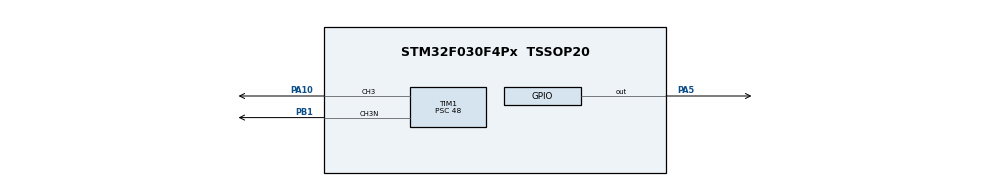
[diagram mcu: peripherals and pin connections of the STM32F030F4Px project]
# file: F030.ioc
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Mcu.Family=STM32F0
Mcu.Name=STM32F030F4Px
Mcu.Package=TSSOP20
PA10.Signal=S_TIM1_CH3
PA13.Mode=Serial_Wire
PA13.Signal=SYS_SWDIO
PA14.Mode=Serial_Wire
PA14.Signal=SYS_SWCLK
PA5.Signal=GPIO_Output
PB1.Mode=Output Compare3 CH3 CH3N
PB1.Signal=TIM1_CH3N
ProjectManager.HeapSize=0x200
ProjectManager.StackSize=0x400
ProjectManager.TargetToolchain=EWARM V8.32
RCC.AHBFreq_Value=48000000
RCC.APB1Freq_Value=48000000
RCC.APB1TimFreq_Value=48000000
RCC.HCLKFreq_Value=48000000
RCC.PLLMUL=RCC_PLL_MUL12
RCC.SYSCLKFreq_VALUE=48000000
RCC.SYSCLKSource=RCC_SYSCLKSOURCE_PLLCLK
SH.S_TIM1_CH3.0=TIM1_CH3,Output Compare3 CH3 CH3N
TIM1.AutomaticOutput=TIM_AUTOMATICOUTPUT_ENABLE
TIM1.Channel-Output\ Compare3\ CH3\ CH3N=TIM_CHANNEL_3
TIM1.DeadTime=5
TIM1.OCMode_3=TIM_OCMODE_TOGGLE
TIM1.OffStateIDLEMode=TIM_OSSI_ENABLE
TIM1.OffStateRunMode=TIM_OSSR_ENABLE
TIM1.Period=10
TIM1.Prescaler=48
board=custom

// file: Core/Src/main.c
/* USER CODE BEGIN Header */
/**
  ******************************************************************************
  * @file           : main.c
  * @brief          : Main program body
  ******************************************************************************
  * @attention
  *
  * Copyright (c) 2025 STMicroelectronics.
  * All rights reserved.
  *
  * This software is licensed under terms that can be found in the LICENSE file
  * in the root directory of this software component.
  * If no LICENSE file comes with this software, it is provided AS-IS.
  *
  ******************************************************************************
  */
/* USER CODE END Header */
#include "main.h"
#include "tim.h"
#include "gpio.h"

/* USER CODE BEGIN PTD */

#define  NO_SOUND       0x00
#define  FREQ_UP        0x01
#define  FREQ_DOWN      0x02

#define DEBUG 0

//#if ((DEBUG == 1))
//#define F_MIN           2000
//#define F_MAX           6000
//#define F_STEP          200
//#else
#define F_MIN           20000
#define F_MAX           60000
#define F_STEP          2000
//#endif
#define F_DIV_ULTRA     1
#define F_DIV_NORMAL    1
/* USER CODE END PTD */

/* USER CODE BEGIN PD */
#define SCEN_MAX        3

/* USER CODE END PD */

/* USER CODE BEGIN PV */

uint8_t direct_dev = 0; // 0 -  ARR , 1 -  ��������� ARR
const uint8_t step_freq = 10;
uint8_t MAX_MIN_ARR[2] = {10, 100};
static uint8_t curr_freq = 10;
uint32_t stop_step_ms =0;
static uint32_t cur_freq = F_MIN;

scenario_t Scenic[SCEN_MAX]={
  {.period_sec          = 60,
  .dir                  = 0,
   .fmin                = F_MIN,
   .f0                  = F_MIN,
   .fmax                = F_MAX,
   .step_freq_Hz        = F_STEP,
   .step_ms             = 5000,//3*1000
   .mode                = FREQ_PULSE
  },

   {.period_sec         = 60,//60*15,
   .dir                 = 0,
   .fmin                = F_MIN,
   .f0                  = F_MIN,
   .fmax                = F_MAX,
   .step_freq_Hz        = F_STEP,
   .step_ms             = 5000,//60*5*1000
   .mode                = FREQ_INCREASE,
   },

   {.period_sec         = 60,
   .dir                 = 0,
   .fmin                = F_MIN,
   .f0                  = F_MIN,
   .fmax                = F_MAX,
   .step_freq_Hz        = F_STEP,
   .step_ms             = 5000,
   .mode                = FREQ_SWING
   },
};

scenic_ctrl_t controller ;
/* USER CODE END PV */

void SystemClock_Config(void);
/* USER CODE BEGIN PFP */
uint8_t get_Freq(uint8_t freq_type)
{
  if(freq_type > 1) freq_type = 0;
  return MAX_MIN_ARR[freq_type];
}

void changeScenario()
{
  if(++controller.indx_scen>=SCEN_MAX)
  {
    controller.indx_scen = 0;
  }
}
void stepFreq(scenario_t *_scen)
{
uint8_t div = controller.freq_div;
    switch(_scen->mode)
    {
      case FREQ_SWING:
      {
        if(_scen->dir)
        {
          _scen->f0 += _scen->step_freq_Hz;
          if(_scen->f0 > _scen->fmax)
          {
            _scen->f0 -= _scen->step_freq_Hz;
            _scen->dir = ~_scen->dir;
          }
        }
        else
        {
          if((_scen->f0 >=_scen->fmin))
          {
            _scen->f0 -= _scen->step_freq_Hz;

          }
           if(_scen->f0 <_scen->fmin)
            {
              _scen->dir = ~_scen->dir;
              _scen->f0 += _scen->step_freq_Hz;
            }
        }

      }
      break;
      case FREQ_INCREASE:
      {
        if(_scen->f0 >= _scen->fmax)
        {
          _scen->f0 = _scen->fmin;
        }
        else
        {
          _scen->f0 += _scen->step_freq_Hz;
        }
      }
      break;
      case FREQ_PULSE:
      {

        if(_scen->dir)
        {
          _scen->dir = 0;
          cur_freq += _scen->step_freq_Hz;

          if(cur_freq > _scen->fmax){
            cur_freq = _scen->fmin;
          }
          _scen->f0 += cur_freq;
        }
        else
        {
          _scen->dir = ~_scen->dir;
          _scen->f0 = 0;
        }
      }
      break;
    }
}

void SetFreq(uint32_t freq_Hz)
{
  uint32_t arr=0;
  // 10000Hz => arr = 100 тиков по 1 мкс
  // 50000Hz => arr = 20 тиков по 1 мкс
  if(freq_Hz !=0)
  {
    arr = (1000000/freq_Hz)/2;// т.к. TIM_OCMODE_TOGGLE то период делим на 2
  }
  TIM_Set_Arr( arr);
}
uint8_t _stepFreq(void)
{
  if( direct_dev)
  {
    if(curr_freq >= MAX_MIN_ARR[ARR_MIN_INDX] && curr_freq <= MAX_MIN_ARR[ARR_MAX_INDX])
    {
      curr_freq -= step_freq;
    }
    else
    {
      direct_dev = !direct_dev;
      curr_freq += step_freq;
    }
  }
  else
  {
    if(curr_freq >= MAX_MIN_ARR[ARR_MIN_INDX] && curr_freq <= MAX_MIN_ARR[ARR_MAX_INDX] )
    {
      curr_freq += step_freq;
    }
    else
    {
      direct_dev = !direct_dev;
      curr_freq -= step_freq;
    }
  }
  return curr_freq;
}
/* USER CODE END PFP */

/* USER CODE BEGIN 0 */
uint8_t st=0;
uint32_t tick =0;
scenario_t *sc;

/* USER CODE END 0 */

int main(void)
{

  /* MCU Configuration--------------------------------------------------------*/

  /* Reset of all peripherals, Initializes the Flash interface and the Systick. */
  LL_APB1_GRP2_EnableClock(LL_APB1_GRP2_PERIPH_SYSCFG);
  LL_APB1_GRP1_EnableClock(LL_APB1_GRP1_PERIPH_PWR);

  /* SysTick_IRQn interrupt configuration */
  NVIC_SetPriority(SysTick_IRQn, 3);

  /* Configure the system clock */
  SystemClock_Config();

  /* USER CODE BEGIN SysInit */
  SysTick_Config(48000);
  /* USER CODE END SysInit */

  /* Initialize all configured peripherals */
  MX_GPIO_Init();
  MX_TIM1_Init();
  /* USER CODE BEGIN 2 */

  sc = &Scenic[controller.indx_scen];
//  stepFreq(sc);
  /* USER CODE END 2 */

  /* Infinite loop */
  /* USER CODE BEGIN WHILE */
  controller.time_start = GetSysTick();
  controller.time_stop  = controller.time_start + sc->period_sec*1000;
  stop_step_ms =  GetSysTick() + sc->step_ms ;
  while (1)
  {
    if(GetSysTick()> controller.time_stop )
    {
      changeScenario();
      sc = &Scenic[controller.indx_scen];
      stepFreq(sc);
      SetFreq(sc->f0);
      controller.time_start = GetSysTick();
      controller.time_stop  = controller.time_start + sc->period_sec*1000;

    }
    if(GetSysTick()> stop_step_ms )
    {
      stepFreq(sc);
      SetFreq(sc->f0);
      stop_step_ms =  GetSysTick() + sc->step_ms ;
    }

    /* USER CODE END WHILE */

  }
}

void SystemClock_Config(void)
{
  LL_FLASH_SetLatency(LL_FLASH_LATENCY_1);
  while(LL_FLASH_GetLatency() != LL_FLASH_LATENCY_1)
  {
  }
  LL_RCC_HSI_Enable();

   /* Wait till HSI is ready */
  while(LL_RCC_HSI_IsReady() != 1)
  {

  }
  LL_RCC_HSI_SetCalibTrimming(16);
  LL_RCC_PLL_ConfigDomain_SYS(LL_RCC_PLLSOURCE_HSI_DIV_2, LL_RCC_PLL_MUL_12);
  LL_RCC_PLL_Enable();

   /* Wait till PLL is ready */
  while(LL_RCC_PLL_IsReady() != 1)
  {

  }
  LL_RCC_SetAHBPrescaler(LL_RCC_SYSCLK_DIV_1);
  LL_RCC_SetAPB1Prescaler(LL_RCC_APB1_DIV_1);
  LL_RCC_SetSysClkSource(LL_RCC_SYS_CLKSOURCE_PLL);

   /* Wait till System clock is ready */
  while(LL_RCC_GetSysClkSource() != LL_RCC_SYS_CLKSOURCE_STATUS_PLL)
  {

  }
  LL_Init1msTick(48000000);
  LL_SetSystemCoreClock(48000000);
}

void Error_Handler(void)
{
  __disable_irq();
  while (1)
  {
  }
}
